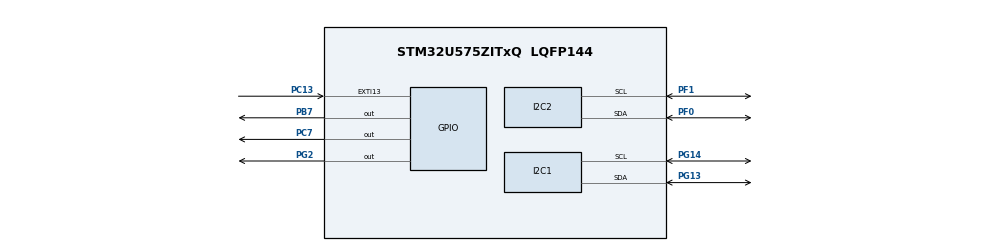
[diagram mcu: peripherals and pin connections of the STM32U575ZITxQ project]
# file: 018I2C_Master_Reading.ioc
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CORTEX_M33_NS.userName=CORTEX_M33
I2C1.Timing=0x00000E14
I2C2.Timing=0x00000E14
Mcu.Family=STM32U5
Mcu.Name=STM32U575ZITxQ
Mcu.Package=LQFP144
NUCLEO-U575ZI-Q.BUTTON=1
NUCLEO-U575ZI-Q.LD1=true
NUCLEO-U575ZI-Q.LD2=true
NUCLEO-U575ZI-Q.LD3=true
NUCLEO-U575ZI-Q.VCP=true
NVIC.EXTI13_IRQn=true\:0\:0\:false\:false\:true\:false\:true\:true
NVIC.I2C2_ER_IRQn=true\:0\:0\:false\:false\:true\:true\:true\:true
NVIC.I2C2_EV_IRQn=true\:0\:0\:false\:false\:true\:true\:true\:true
NVIC.PriorityGroup=NVIC_PRIORITYGROUP_3
NVIC.TIM17_IRQn=true\:7\:0\:false\:false\:true\:false\:true\:true
NVIC.TimeBase=TIM17_IRQn
NVIC.TimeBaseIP=TIM17
PA10.Signal=USART1_RX
PA13\ (JTMS/SWDIO).Signal=DEBUG_JTMS-SWDIO
PA14\ (JTCK/SWCLK).Signal=DEBUG_JTCK-SWCLK
PA9.Signal=USART1_TX
PB3\ (JTDO/TRACESWO).Signal=DEBUG_JTDO-SWO
PB7.Signal=GPIO_Output
PC13.Signal=GPXTI13
PC14-OSC32_IN\ (PC14).Signal=RCC_OSC32_IN
PC15-OSC32_OUT\ (PC15).Signal=RCC_OSC32_OUT
PC7.Signal=GPIO_Output
PF0.GPIO_Pu=GPIO_PULLUP
PF0.Mode=I2C
PF0.Signal=I2C2_SDA
PF1.GPIO_Pu=GPIO_PULLUP
PF1.Mode=I2C
PF1.Signal=I2C2_SCL
PG13.GPIO_Pu=GPIO_PULLUP
PG13.Mode=I2C
PG13.Signal=I2C1_SDA
PG14.GPIO_Pu=GPIO_PULLUP
PG14.Mode=I2C
PG14.Signal=I2C1_SCL
PG2.Signal=GPIO_Output
PWR.PowerMode=PWR_SMPS_SUPPLY
ProjectManager.HeapSize=0x200
ProjectManager.StackSize=0x400
ProjectManager.TargetToolchain=STM32CubeIDE
RCC.ADCFreq_Value=16000000
RCC.DACCLockSelectionVirtual=RCC_DAC1CLKSOURCE_LSI
RCC.EPOD_VALUE=4000000
RCC.HSE_VALUE=16000000
RCC.HSI48_VALUE=48000000
RCC.HSI_VALUE=16000000
RCC.LSE_VALUE=32768
RCC.LSIDIV_VALUE=32000
RCC.MSI_VALUE=4000000
RCC.USBFreq_Value=48000000
RCC.VCOOutputFreq_Value=516000000
VP_ICACHE_VS_ENABLE_ICACHE_MEMORY.Mode=Memoryregions
VP_ICACHE_VS_ICACHE.Mode=DirectMappedCache
VP_LPBAMQUEUE_VS_QUEUE.Mode=QUEUEMODE
VP_LPBAM_VS_SIG1.Mode=SmartRun
VP_LPBAM_VS_SIG4.Mode=LPDMA1
VP_MEMORYMAP_VS_MEMORYMAP.Mode=CurAppReg
VP_NUCLEO-U575ZI-Q_VS_BSP_COMMON.Mode=COMMON
VP_PWR_VS_DBSignals.Mode=DisableDeadBatterySignals
VP_PWR_VS_LPOM.Mode=PowerOptimisation
VP_PWR_VS_SECSignals.Mode=Security/Privilege
VP_SYS_VS_tim17.Mode=TIM17
board=NUCLEO-U575ZI-Q

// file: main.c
/* USER CODE BEGIN Header */
/**
  ******************************************************************************
  * @file           : main.c
  * @brief          : Main program body
  ******************************************************************************
  * @attention
  *
  * Copyright (c) 2026 STMicroelectronics.
  * All rights reserved.
  *
  * This software is licensed under terms that can be found in the LICENSE file
  * in the root directory of this software component.
  * If no LICENSE file comes with this software, it is provided AS-IS.
  *
  ******************************************************************************
  */
/* USER CODE END Header */
#include "main.h"

COM_InitTypeDef BspCOMInit;

I2C_HandleTypeDef hi2c1;
I2C_HandleTypeDef hi2c2;

/* USER CODE BEGIN PV */

uint8_t master_rx_buffer[4] = {0x00, 0x00, 0x00, 0x00};
uint8_t slave_tx_buffer[4]  = {0x11, 0x22, 0x33, 0x44};
volatile uint8_t transfer_complete = 0;

/* USER CODE END PV */

void SystemClock_Config(void);
static void SystemPower_Config(void);
static void MX_GPIO_Init(void);
static void MX_ICACHE_Init(void);
static void MX_I2C1_Init(void);
static void MX_I2C2_Init(void);

int main(void)
{

  /* MCU Configuration--------------------------------------------------------*/

  /* Reset of all peripherals, Initializes the Flash interface and the Systick. */
  HAL_Init();

  /* Configure the System Power */
  SystemPower_Config();

  /* Configure the system clock */
  SystemClock_Config();

  /* Initialize all configured peripherals */
  MX_GPIO_Init();
  MX_ICACHE_Init();
  MX_I2C1_Init();
  MX_I2C2_Init();

  /* Initialize leds */
  BSP_LED_Init(LED_GREEN);
  BSP_LED_Init(LED_BLUE);
  BSP_LED_Init(LED_RED);

  /* Initialize USER push-button, will be used to trigger an interrupt each time it's pressed.*/
  BSP_PB_Init(BUTTON_USER, BUTTON_MODE_EXTI);

  /* Initialize COM1 port (115200, 8 bits (7-bit data + 1 stop bit), no parity */
  BspCOMInit.BaudRate   = 115200;
  BspCOMInit.WordLength = COM_WORDLENGTH_8B;
  BspCOMInit.StopBits   = COM_STOPBITS_1;
  BspCOMInit.Parity     = COM_PARITY_NONE;
  BspCOMInit.HwFlowCtl  = COM_HWCONTROL_NONE;
  if (BSP_COM_Init(COM1, &BspCOMInit) != BSP_ERROR_NONE)
  {
    Error_Handler();
  }

  /* Infinite loop */
  /* USER CODE BEGIN WHILE */
  while (1)
  {
	  HAL_I2C_Master_Receive(&hi2c1, (100 << 1), master_rx_buffer, 4, 100);

	  HAL_Delay(1000);

    /* USER CODE END WHILE */

  }
}

void SystemClock_Config(void)
{
  RCC_OscInitTypeDef RCC_OscInitStruct = {0};
  RCC_ClkInitTypeDef RCC_ClkInitStruct = {0};

  /** Configure the main internal regulator output voltage
  */
  if (HAL_PWREx_ControlVoltageScaling(PWR_REGULATOR_VOLTAGE_SCALE4) != HAL_OK)
  {
    Error_Handler();
  }

  /** Initializes the CPU, AHB and APB buses clocks
  */
  RCC_OscInitStruct.OscillatorType = RCC_OSCILLATORTYPE_MSI;
  RCC_OscInitStruct.MSIState = RCC_MSI_ON;
  RCC_OscInitStruct.MSICalibrationValue = RCC_MSICALIBRATION_DEFAULT;
  RCC_OscInitStruct.MSIClockRange = RCC_MSIRANGE_4;
  RCC_OscInitStruct.PLL.PLLState = RCC_PLL_NONE;
  if (HAL_RCC_OscConfig(&RCC_OscInitStruct) != HAL_OK)
  {
    Error_Handler();
  }

  /** Initializes the CPU, AHB and APB buses clocks
  */
  RCC_ClkInitStruct.ClockType = RCC_CLOCKTYPE_HCLK|RCC_CLOCKTYPE_SYSCLK
                              |RCC_CLOCKTYPE_PCLK1|RCC_CLOCKTYPE_PCLK2
                              |RCC_CLOCKTYPE_PCLK3;
  RCC_ClkInitStruct.SYSCLKSource = RCC_SYSCLKSOURCE_MSI;
  RCC_ClkInitStruct.AHBCLKDivider = RCC_SYSCLK_DIV1;
  RCC_ClkInitStruct.APB1CLKDivider = RCC_HCLK_DIV1;
  RCC_ClkInitStruct.APB2CLKDivider = RCC_HCLK_DIV1;
  RCC_ClkInitStruct.APB3CLKDivider = RCC_HCLK_DIV1;

  if (HAL_RCC_ClockConfig(&RCC_ClkInitStruct, FLASH_LATENCY_0) != HAL_OK)
  {
    Error_Handler();
  }
}

/**
  * @brief Power Configuration
  * @retval None
  */
static void SystemPower_Config(void)
{
  HAL_PWREx_EnableVddIO2();

  /*
   * Disable the internal Pull-Up in Dead Battery pins of UCPD peripheral
   */
  HAL_PWREx_DisableUCPDDeadBattery();

  /*
   * Switch to SMPS regulator instead of LDO
   */
  if (HAL_PWREx_ConfigSupply(PWR_SMPS_SUPPLY) != HAL_OK)
  {
    Error_Handler();
  }
}

static void MX_I2C1_Init(void)
{

  hi2c1.Instance = I2C1;
  hi2c1.Init.Timing = 0x00000E14;
  hi2c1.Init.OwnAddress1 = 0;
  hi2c1.Init.AddressingMode = I2C_ADDRESSINGMODE_7BIT;
  hi2c1.Init.DualAddressMode = I2C_DUALADDRESS_DISABLE;
  hi2c1.Init.OwnAddress2 = 0;
  hi2c1.Init.OwnAddress2Masks = I2C_OA2_NOMASK;
  hi2c1.Init.GeneralCallMode = I2C_GENERALCALL_DISABLE;
  hi2c1.Init.NoStretchMode = I2C_NOSTRETCH_DISABLE;
  if (HAL_I2C_Init(&hi2c1) != HAL_OK)
  {
    Error_Handler();
  }

  /** Configure Analogue filter
  */
  if (HAL_I2CEx_ConfigAnalogFilter(&hi2c1, I2C_ANALOGFILTER_ENABLE) != HAL_OK)
  {
    Error_Handler();
  }

  /** Configure Digital filter
  */
  if (HAL_I2CEx_ConfigDigitalFilter(&hi2c1, 0) != HAL_OK)
  {
    Error_Handler();
  }

}

static void MX_I2C2_Init(void)
{

  hi2c2.Instance = I2C2;
  hi2c2.Init.Timing = 0x00000E14;
  hi2c2.Init.OwnAddress1 = 100;
  hi2c2.Init.AddressingMode = I2C_ADDRESSINGMODE_7BIT;
  hi2c2.Init.DualAddressMode = I2C_DUALADDRESS_DISABLE;
  hi2c2.Init.OwnAddress2 = 0;
  hi2c2.Init.OwnAddress2Masks = I2C_OA2_NOMASK;
  hi2c2.Init.GeneralCallMode = I2C_GENERALCALL_DISABLE;
  hi2c2.Init.NoStretchMode = I2C_NOSTRETCH_DISABLE;
  if (HAL_I2C_Init(&hi2c2) != HAL_OK)
  {
    Error_Handler();
  }

  /** Configure Analogue filter
  */
  if (HAL_I2CEx_ConfigAnalogFilter(&hi2c2, I2C_ANALOGFILTER_ENABLE) != HAL_OK)
  {
    Error_Handler();
  }

  /** Configure Digital filter
  */
  if (HAL_I2CEx_ConfigDigitalFilter(&hi2c2, 0) != HAL_OK)
  {
    Error_Handler();
  }

}

static void MX_ICACHE_Init(void)
{

  /** Enable instruction cache in 1-way (direct mapped cache)
  */
  if (HAL_ICACHE_ConfigAssociativityMode(ICACHE_1WAY) != HAL_OK)
  {
    Error_Handler();
  }
  if (HAL_ICACHE_Enable() != HAL_OK)
  {
    Error_Handler();
  }

}

static void MX_GPIO_Init(void)
{

  /* GPIO Ports Clock Enable */
  __HAL_RCC_GPIOC_CLK_ENABLE();
  __HAL_RCC_GPIOF_CLK_ENABLE();
  __HAL_RCC_GPIOA_CLK_ENABLE();
  __HAL_RCC_GPIOG_CLK_ENABLE();
  __HAL_RCC_GPIOB_CLK_ENABLE();

}

/* USER CODE BEGIN 4 */

//void HAL_I2C_SlaveRxCpltCallback(I2C_HandleTypeDef *hi2c)
//{
//    if(hi2c->Instance == I2C2)
//    {
//        transfer_complete = 1;
//        BSP_LED_Toggle(LED_GREEN);
//        HAL_I2C_Slave_Receive_IT(&hi2c2, slave_rx_buffer, 4);
//    }
//}

// NEW CALLBACK FOR THIS PRACTICAL
void HAL_I2C_SlaveTxCpltCallback(I2C_HandleTypeDef *hi2c)
{
    if(hi2c->Instance == I2C2) // Check if the transfer finished on our Slave instance
    {
        transfer_complete = 1;

        // Toggle the BLUE LED to indicate the slave successfully pushed data to the master!
        BSP_LED_Toggle(LED_BLUE);

        // Re-prime the slave so it is ready to transmit data again on the next master poll
        HAL_I2C_Slave_Transmit_IT(&hi2c2, slave_tx_buffer, 4);
    }
}

/* USER CODE END 4 */

void HAL_TIM_PeriodElapsedCallback(TIM_HandleTypeDef *htim)
{
  if (htim->Instance == TIM17)
  {
    HAL_IncTick();
  }
}

void Error_Handler(void)
{
  __disable_irq();
  while (1)
  {
  }
}
